AUTOSAR XML
package /EvSwcs
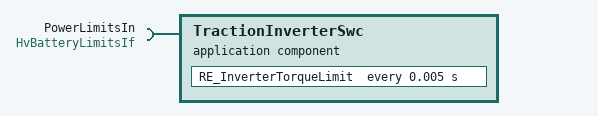
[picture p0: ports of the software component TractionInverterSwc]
  application sw component type TractionInverterSwc
    require port PowerLimitsIn: required-interface=HvBatteryLimitsIf
    behavior TractionInverter_IB
      runnable RE_InverterTorqueLimit: execution-time-wcet=0.0012
      timing event TE_Inv_5ms: start-on-event=RE_InverterTorqueLimit, period=0.005
